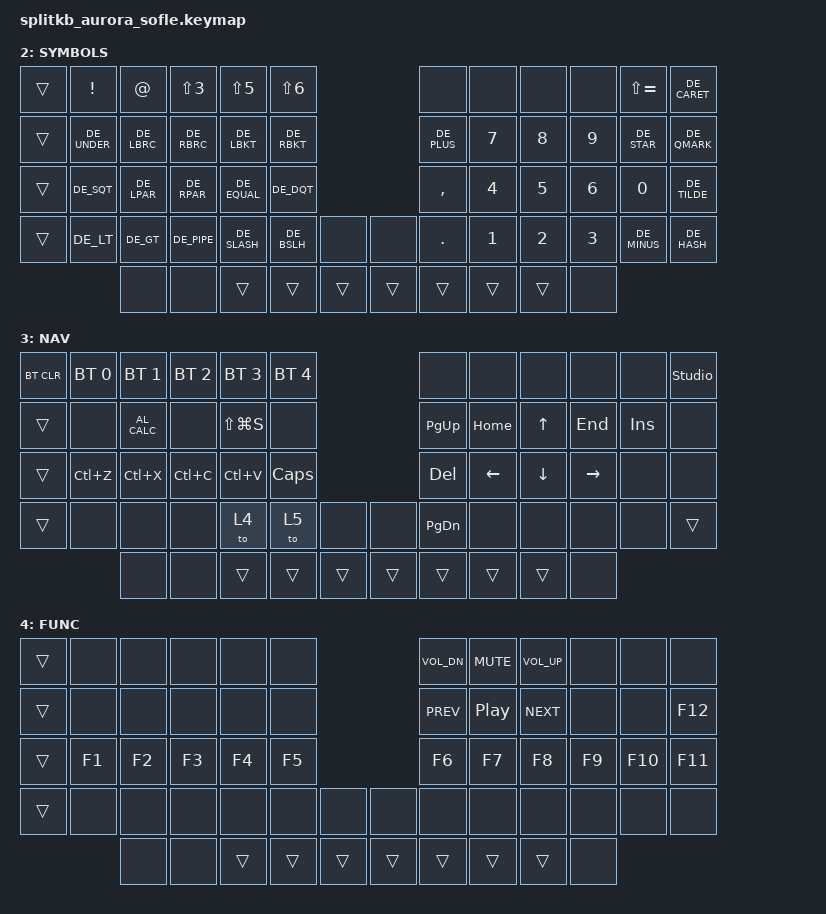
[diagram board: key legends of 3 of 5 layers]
#include "keys_de.h"
/* use helper macros to define left and right hand keys */
#include "zmk-helpers/helper.h"
#include "zmk-helpers/key-labels/sofle.h"                                              // key-position labels
#include <behaviors.dtsi>
#include <dt-bindings/zmk/bt.h>
#include <dt-bindings/zmk/keys.h>

#define KEYS_L LT0 LT1 LT2 LT3 LT4 LT5 LM0 LM1 LM2 LM3 LM4 LM5 LB0 LB1 LB2 LB3 LB4 LB5 // left-hand keys
#define KEYS_R RT0 RT1 RT2 RT3 RT4 RT5 RM0 RM1 RM2 RM3 RM4 RM5 RB0 RB1 RB2 RB3 RB4 LB5 // right-hand keys
#define THUMBS LH4 LH3 LH2 LH1 LH0 RH0 RH1 RH2 RH3 RH4                                 // thumb keys

#define XXX &none
#define ___ &trans

#define MAKE_HRM(NAME, HOLD, TAP, TRIGGER_POS) \
    ZMK_HOLD_TAP(NAME, \
        flavor = "balanced"; \
        tapping-term-ms = <280>; \
        quick-tap-ms = <175>; \
        require-prior-idle-ms = <150>; \
        bindings = <HOLD>, <TAP>; \
        hold-trigger-key-positions = <TRIGGER_POS>; \
        hold-trigger-on-release; \
    )

MAKE_HRM(hml, &kp, &kp, KEYS_R THUMBS) // Left-hand HRMs.
MAKE_HRM(hmr, &kp, &kp, KEYS_L THUMBS) // Right-hand HRMs.

ZMK_HOLD_TAP(noptap, 
    flavor = "balanced";
    tapping-term-ms = <280>; 
    quick-tap-ms = <175>; 
    require-prior-idle-ms = <150>; 
    bindings = <&to>, <&none>; 
)

ZMK_COMBO(combo_question, &kp LS(MINUS), 10 11) 
ZMK_COMBO(combo_oe, &kp SEMI, 34 35) 


ZMK_LAYER(colemak, 
    //╭─────────────┬─────────────┬─────────────┬─────────────┬─────────────┬─────────────╮                             ╭─────────────┬─────────────┬─────────────┬─────────────┬─────────────┬─────────────╮
        &kp ESC       &kp DE_N1     &kp DE_N2     &kp DE_N3     &kp DE_N4     &kp DE_N5                                   &kp DE_N6     &kp DE_N7     &kp DE_N8     &kp DE_N9     &kp DE_N0     &kp MINUS    
    //├─────────────┼─────────────┼─────────────┼─────────────┼─────────────┼─────────────┤                             ├─────────────┼─────────────┼─────────────┼─────────────┼─────────────┼─────────────┤
        XXX           &kp Q         &kp W         &kp F         &kp P         &kp B                                       &kp J         &kp L         &kp U         &kp Y         &kp PERIOD    &kp LBKT
    //├─────────────┼─────────────┼─────────────┼─────────────┼─────────────┼─────────────┤                             ├─────────────┼─────────────┼─────────────┼─────────────┼─────────────┼─────────────┤
        &kp TAB       &hml LSHFT A  &hml LALT R   &hml LGUI S   &hml LCTRL T  &kp G                                       &kp M         &hmr LCTRL N  &hmr LGUI E  &hmr LALT I   &hmr LSHFT O   &kp SQT
    //├─────────────┼─────────────┼─────────────┼─────────────┼─────────────┼─────────────┼─────────────┤ ├─────────────┼─────────────┼─────────────┼─────────────┼─────────────┼─────────────┼─────────────┤
        &kp LCTL      &kp Z         &kp X         &kp C         &kp D         &kp V         XXX             XXX           &kp K         &kp H         &kp COMMA     &kp PERIOD    &kp SLASH     &kp NUBS
    //╰─────────────┴─────────────┴─────────────┴─────────────┴─────────────┴─────────────┴─────────────┤ ├─────────────┴─────────────┴─────────────┴─────────────┴─────────────┴─────────────┴─────────────╯
                                     XXX           XXX           &lt 4 LALT    &kp LSHFT     &lt 2 ENTER    &mo 3         &kp SPACE     &kp BSPC      &kp RALT      &noptap 1 XXX   
    //                            ╰─────────────┴─────────────┴─────────────┴─────────────┴─────────────╯ ╰─────────────┴─────────────┴─────────────┴─────────────┴─────────────╯
)

ZMK_LAYER(QWERTZ,
    //╭─────────────┬─────────────┬─────────────┬─────────────┬─────────────┬─────────────╮                             ╭─────────────┬─────────────┬─────────────┬─────────────┬─────────────┬─────────────╮
        ___           &kp DE_N1     &kp DE_N2     &kp DE_N3     &kp DE_N4     &kp DE_N5                                   &kp DE_N6     &kp DE_N7     &kp DE_N8     &kp DE_N9     &kp DE_N0     &kp MINUS    
    //├─────────────┼─────────────┼─────────────┼─────────────┼─────────────┼─────────────┤                             ├─────────────┼─────────────┼─────────────┼─────────────┼─────────────┼─────────────┤
        ___           &kp Q         &kp W         &kp E         &kp R         &kp T                                       &kp Y         &kp U         &kp I         &kp O         &kp P         &kp LBKT
    //├─────────────┼─────────────┼─────────────┼─────────────┼─────────────┼─────────────┤                             ├─────────────┼─────────────┼─────────────┼─────────────┼─────────────┼─────────────┤
        ___           &hml LSHFT A  &hml LALT S   &hml LGUI D   &hml LCTRL F  &kp G                                       &kp H         &hmr LCTRL J  &hmr LGUI K   &hmr LALT L  &hmr LSHFT SEMI &kp SQT
    //├─────────────┼─────────────┼─────────────┼─────────────┼─────────────┼─────────────┼─────────────┤ ├─────────────┼─────────────┼─────────────┼─────────────┼─────────────┼─────────────┼─────────────┤
        ___           &kp Z         &kp X         &kp C         &kp V         &kp B         XXX             XXX           &kp N         &kp M         &kp COMMA     &kp PERIOD    &kp SLASH     &kp NUBS
    //╰─────────────┴─────────────┴─────────────┴─────────────┴─────────────┴─────────────┴─────────────┤ ├─────────────┴─────────────┴─────────────┴─────────────┴─────────────┴─────────────┴─────────────╯
                                    XXX           XXX           ___           ___           ___             ___           ___           ___           ___           &noptap 0 XXX  
    //                            ╰─────────────┴─────────────┴─────────────┴─────────────┴─────────────╯ ╰─────────────┴─────────────┴─────────────┴─────────────┴─────────────╯
)

ZMK_LAYER(SYMBOLS,
    //╭─────────────┬─────────────┬─────────────┬─────────────┬─────────────┬─────────────╮                             ╭─────────────┬─────────────┬─────────────┬─────────────┬─────────────┬─────────────╮
        ___           &kp EXCL      &kp AT        &kp LS(N3)    &kp LS(N5)    &kp LS(N6)                                  XXX           XXX            XXX           XXX          &kp LS(EQUAL) &kp DE_CARET
    //├─────────────┼─────────────┼─────────────┼─────────────┼─────────────┼─────────────┤                             ├─────────────┼─────────────┼─────────────┼─────────────┼─────────────┼─────────────┤
        ___           &kp DE_UNDER  &kp DE_LBRC   &kp DE_RBRC   &kp DE_LBKT   &kp DE_RBKT                                 &kp DE_PLUS   &kp N7        &kp N8        &kp N9        &kp DE_STAR   &kp DE_QMARK
    //├─────────────┼─────────────┼─────────────┼─────────────┼─────────────┼─────────────┤                             ├─────────────┼─────────────┼─────────────┼─────────────┼─────────────┼─────────────┤
        ___           &kp DE_SQT    &kp DE_LPAR   &kp DE_RPAR   &kp DE_EQUAL  &kp DE_DQT                                  &kp COMMA     &kp N4        &kp N5        &kp N6        &kp N0        &kp DE_TILDE
    //├─────────────┼─────────────┼─────────────┼─────────────┼─────────────┼─────────────┼─────────────┤ ├─────────────┼─────────────┼─────────────┼─────────────┼─────────────┼─────────────┤
        ___           &kp DE_LT     &kp DE_GT     &kp DE_PIPE   &kp DE_SLASH  &kp DE_BSLH   XXX             XXX           &kp DOT       &kp N1        &kp N2        &kp N3        &kp DE_MINUS  &kp DE_HASH
    //╰─────────────┴─────────────┴─────────────┴─────────────┴─────────────┴─────────────┴─────────────┤ ├─────────────┴─────────────┴─────────────┴─────────────┴─────────────┴─────────────┴─────────────╯
                                    XXX           XXX           ___           ___           ___             ___           ___           ___           ___           XXX  
    //                            ╰─────────────┴─────────────┴─────────────┴─────────────┴─────────────╯ ╰─────────────┴─────────────┴─────────────┴─────────────┴─────────────╯
)


ZMK_LAYER(NAV,    
    //╭─────────────┬─────────────┬─────────────┬─────────────┬─────────────┬─────────────╮                             ╭─────────────┬─────────────┬─────────────┬─────────────┬─────────────┬─────────────╮
        &bt BT_CLR    &bt BT_SEL 0  &bt BT_SEL 1  &bt BT_SEL 2  &bt BT_SEL 3  &bt BT_SEL 4                                XXX           XXX           XXX           XXX           XXX          &studio_unlock   
    //├─────────────┼─────────────┼─────────────┼─────────────┼─────────────┼─────────────┤                             ├─────────────┼─────────────┼─────────────┼─────────────┼─────────────┼─────────────┤
        ___           XXX           &kp C_AL_CALC XXX           &kp LS(LG(S)) XXX                                         &kp PAGE_UP   &kp HOME      &kp UP_ARROW  &kp END       &kp INSERT    XXX  
    //├─────────────┼─────────────┼─────────────┼─────────────┼─────────────┼─────────────┤                             ├─────────────┼─────────────┼─────────────┼─────────────┼─────────────┼─────────────┤
        ___           &kp LC(Z)     &kp LC(X)     &kp LC(C)     &kp LC(V)     &kp CAPSLOCK                                &kp DELETE    &kp LEFT      &kp DOWN      &kp RIGHT     XXX           XXX  
    //├─────────────┼─────────────┼─────────────┼─────────────┼─────────────┼─────────────┼─────────────┤ ├─────────────┼─────────────┼─────────────┼─────────────┼─────────────┼─────────────┼─────────────┤
        ___           XXX           XXX           XXX           &to 4         &to 5         XXX             XXX           &kp PAGE_DOWN XXX           XXX           XXX           XXX           ___   
    //╰─────────────┴─────────────┴─────────────┴─────────────┴─────────────┴─────────────┴─────────────┤ ├─────────────┴─────────────┴─────────────┴─────────────┴─────────────┴─────────────┴─────────────╯
                                    XXX           XXX           ___           ___           ___             ___           ___           ___           ___           XXX  
    //                            ╰─────────────┴─────────────┴─────────────┴─────────────┴─────────────╯ ╰─────────────┴─────────────┴─────────────┴─────────────┴─────────────╯
)

ZMK_LAYER(FUNC,
    //╭─────────────┬─────────────┬─────────────┬─────────────┬─────────────┬─────────────╮                             ╭─────────────┬─────────────┬─────────────┬─────────────┬─────────────┬─────────────╮
        ___           XXX           XXX           XXX           XXX           XXX                                         &kp C_VOL_DN  &kp C_MUTE    &kp C_VOL_UP  XXX           XXX           XXX   
    //├─────────────┼─────────────┼─────────────┼─────────────┼─────────────┼─────────────┤                             ├─────────────┼─────────────┼─────────────┼─────────────┼─────────────┼─────────────┤
        ___           XXX           XXX           XXX           XXX           XXX                                         &kp C_PREV    &kp C_PP      &kp C_NEXT    XXX           XXX           &kp F12
    //├─────────────┼─────────────┼─────────────┼─────────────┼─────────────┼─────────────┤                             ├─────────────┼─────────────┼─────────────┼─────────────┼─────────────┼─────────────┤
        ___           &kp F1        &kp F2        &kp F3        &kp F4        &kp F5                                      &kp F6        &kp F7        &kp F8        &kp F9        &kp F10       &kp F11
    //├─────────────┼─────────────┼─────────────┼─────────────┼─────────────┼─────────────┼─────────────┤ ├─────────────┼─────────────┼─────────────┼─────────────┼─────────────┼─────────────┼─────────────┤
        ___           XXX           XXX           XXX           XXX           XXX           XXX             XXX           XXX           XXX           XXX           XXX           XXX           XXX   
    //╰─────────────┴─────────────┴─────────────┴─────────────┴─────────────┴─────────────┴─────────────┤ ├─────────────┴─────────────┴─────────────┴─────────────┴─────────────┴─────────────┴─────────────╯
                                    XXX           XXX           ___           ___           ___             ___           ___           ___           ___           XXX  
    //                            ╰─────────────┴─────────────┴─────────────┴─────────────┴─────────────╯ ╰─────────────┴─────────────┴─────────────┴─────────────┴─────────────╯
)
